# CALC3_IPGW_ICONT register map
Vendor: Texas Instruments
Peripheral module from a debugger description file (folder DRA75x_DRA74x).
Registers are 32-bit, access not given, reset 0x0 unless marked. A register's access mark holds for its fields unless they carry their own. Offsets are as the file gives them; lines under a group give offsets from that group; [hi:lo] are bit positions; {n}, {i} and the like mark numbered series; 'fields as' and 'values as' point back to an identical list; <NAME> marks a mode.

## CALC3_IPGW_ICONT
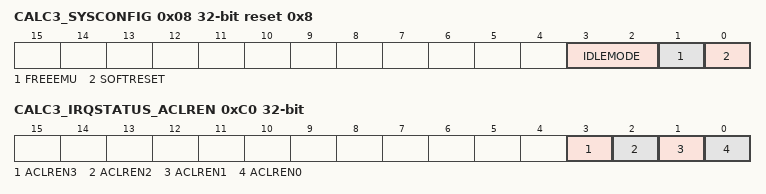
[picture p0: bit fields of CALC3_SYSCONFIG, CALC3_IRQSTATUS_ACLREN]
0x08 CALC3_SYSCONFIG access per field reset 0x8 — Clock management configuration
  [3:2] IDLEMODE rw — Configuration of the local target state management mode.By definition, target can handle read/write transaction as long as it is out of IDLE state. . Backup mode, for debug only. . Backup mode, for debug only. . IP module shall not generate (IRQ- or DMA-request-related) wakeup events. . IP module may generate (IRQ- or DMA-request-related) wakeup events when in IDLE state. .
    0=IDLE_IDLE_IP_0 (Force-idle mode: local target's IDLE state follows (acknowledges) the system's IDLE requests unconditionally; that is, regardless of the IP module's internal requirements.); 1=IDLE_1 (No-idle mode: local target never enters IDLE state.); 2=IDLE_IP_2 (Smart-idle mode: local target's IDLE state eventually follows (acknowledges) the system's idle requests, depending on the IP module's internal requirements.); 3=IDLE_IDLE_IP_3 (Smart-idle wakeup-capable mode: local target's IDLE state eventually follows (acknowledges) the system's IDLE requests, depending on the IP module's internal requirements.)
  [1] FREEEMU rw — Sensitivity to emulation (debug) suspend input signal.
    0=IP_0 (IP module is sensitive to emulation suspend); 1=IP_1 (IP module is not sensitive to emulation suspend)
  [0] SOFTRESET rw — Software reset
    0=Reset_done,_no_pending_action; 1=Reset_(software_or_other)_ongoing; 0=No_action; 1=Initiate_software_reset
0x0C CALC3_IRQ_EOI access per field — End Of Interrupt number specification
  [1:0] LINE_NUMBER rw — Software End Of Interrupt (EOI) control. Write number of interrupt output.
    0=EOI_(LSE)_0 (EOI for interrupt output int_end load (LSE)); 1=EOI_(CALC3_1 (EOI for interrupt output int_end (CALC3 Core)); 2=EOI_(LSE)_2 (EOI for interrupt output int_end store (LSE)); 3=EOI_(LSE)_3 (EOI for interrupt output int_undef (LSE)); 0=Reads_always_0_(no_EOI_memory)
0x14 CALC3_IPQSTATUS_RAW_0 — Per-event raw interrupt status vector, int_end load (LSE). Raw status is set even if event is not enabled. Write 1 to set the (raw) status, mostly for debug.
  [0] EVENT0 — Settable raw status for int_end load (LSE). Write 0: No action Read 0: No event pending Read 1: Event pending Write 1: Set event (debug) (access RW W1toSet)
0x18 CALC3_IPQSTATUS_RAW_1 — Per-event raw interrupt status vector, int_end (CALC3 core). Raw status is set even if event is not enabled. Write 1 to set the (raw) status, mostly for debug.
  [0] EVENT0 — Settable raw status for int_end (CALC3 core). Write 0: No action Read 0: No event pending Read 1: Event pending Write 1: Set event (debug) (access RW W1toSet)
0x1C CALC3_IPQSTATUS_RAW_2 — Per-event raw interrupt status vector, int_end store (LSE). Raw status is set even if event is not enabled. Write 1 to set the (raw) status, mostly for debug.
  [0] EVENT0 — Settable raw status for int_end store (LSE). Write 0: No action Read 0: No event pending Read 1: Event pending Write 1: Set event (debug) (access RW W1toSet)
0x20 CALC3_IPQSTATUS_RAW_3 — Per-event raw interrupt status vector, int_undef (LSE). Raw status is set even if event is not enabled. Write 1 to set the (raw) status, mostly for debug.
  [0] EVENT0 — Settable raw status for int_undef (LSE). Write 0: No action Read 0: No event pending Read 1: Event pending Write 1: Set event (debug) (access RW W1toSet)
0x30 CALC3_IRQSTATUS_0 — Per-event 'enabled' interrupt status vector, int_end load (LSE). Enabled status is not set unless event is enabled. Write 1 to clear the status after interrupt has been serviced (raw status gets cleared, that is, even if not enabled).
  [0] EVENT0 — Clearable, enabled status for int_end load (LSE). Write 0: No action Read 0: No (enabled) event pending Read 1: Event pending Write 1: Clear (raw) event (access RW W1toClr)
0x34 CALC3_IRQSTATUS_1 — Per-event 'enabled' interrupt status vector, int_end (CALC3 Core). Enabled status is not set unless event is enabled. Write 1 to clear the status after interrupt has been serviced (raw status gets cleared, that is, even if not enabled).
  [0] EVENT0 — Clearable, enabled status for int_end (CALC3 core). Write 0: No action Read 0: No (enabled) event pending Read 1: Event pending Write 1: Clear (raw) event (access RW W1toClr)
0x38 CALC3_IRQSTATUS_2 — Per-event 'enabled' interrupt status vector, int_end store (LSE). Enabled status is not set unless event is enabled. Write 1 to clear the status after interrupt has been serviced (raw status gets cleared, that is, even if not enabled).
  [0] EVENT0 — Clearable, enabled status for int_end store (LSE) Write 0: No action Read 0: No (enabled) event pending Read 1: Event pending Write 1: Clear (raw) event (access RW W1toClr)
0x3C CALC3_IRQSTATUS_3 — Per-event 'enabled' interrupt status vector, int_undef (LSE). Enabled status is not set unless event is enabled. Write 1 to clear the status after interrupt has been serviced (raw status gets cleared, that is, even if not enabled).
  [0] EVENT0 — Clearable, enabled status for int_undef (LSE). Write 0: No action Read 0: No (enabled) event pending Read 1: Event pending Write 1: Clear (raw) event (access RW W1toClr)
0x4C CALC3_IRQENABLE_SET_0 — Per-event interrupt enable bit vector, int_end load (LSE). Write 1 to set (enable interrupt). Readout equal to corresponding _CLR register.
  [0] ENABLE0 — Enable for int_end load (LSE) Write 0: No action Read 0: Interrupt disabled (masked) Read 1: Interrupt enabled Write 1: Enable interrupt (access RW W1toSet)
0x50 CALC3_IRQENABLE_SET_1 — Per-event interrupt enable bit vector, int_end (CALC3 core). Write 1 to set (enable interrupt). Readout equal to corresponding _CLR register.
  [0] ENABLE0 — Enable for int_end (CALC3 core) Write 0: No action Read 0: Interrupt disabled (masked) Read 1: Interrupt enabled Write 1: Enable interrupt (access RW W1toSet)
0x54 CALC3_IRQENABLE_SET_2 — Per-event interrupt enable bit vector, int_end store (LSE). Write 1 to set (enable interrupt). Readout equal to corresponding _CLR register.
  [0] ENABLE0 — Enable for int_end store (LSE) Write 0: No action Read 0: Interrupt disabled (masked) Read 1: Interrupt enabled Write 1: Enable interrupt (access RW W1toSet)
0x58 CALC3_IRQENABLE_SET_3 — Per-event interrupt enable bit vector, int_undef (LSE). Write 1 to set (enable interrupt). Readout equal to corresponding _CLR register.
  [0] ENABLE0 — Enable for int_undef (LSE) Write 0: No action Read 0: Interrupt disabled (masked) Read 1: Interrupt enabled Write 1: Enable interrupt (access RW W1toSet)
0x68 CALC3_IRQENABLE_CLR_0 — Per-event interrupt enable bit vector, int_end load (LSE). Write 1 to clear (disable interrupt). Readout equal to corresponding _SET register.
  [0] ENABLE0 — Enable for int_end load (LSE) Write 0: No action Read 0: Interrupt disabled (masked) Read 1: Interrupt enabled Write 1: Disable interrupt (access RW W1toClr)
0x6C CALC3_IRQENABLE_CLR_1 — Per-event interrupt enable bit vector, int_end (CALC3 core). Write 1 to clear (disable interrupt). Readout equal to corresponding _SET register.
  [0] ENABLE0 — Enable for int_end (CALC3 core) Write 0: No action Read 0: Interrupt disabled (masked) Read 1: Interrupt enabled Write 1: Disable interrupt (access RW W1toClr)
0x70 CALC3_IRQENABLE_CLR_2 — Per-event interrupt enable bit vector, int_end store (LSE). Write 1 to clear (disable interrupt). Readout equal to corresponding _SET register.
  [0] ENABLE0 — Enable for int_end store (LSE) Write 0: No action Read 0: Interrupt disabled (masked) Read 1: Interrupt enabled Write 1: Disable interrupt (access RW W1toClr)
0x74 CALC3_IRQENABLE_CLR_3 — Per-event interrupt enable bit vector, int_undef (LSE). Write 1 to clear (disable interrupt). Readout equal to corresponding _SET register.
  [0] ENABLE0 — Enable for int_undef (LSE) Write 0: No action Read 0: Interrupt disabled (masked) Read 1: Interrupt enabled Write 1: Disable interrupt (access RW W1toClr)
0xC0 CALC3_IRQSTATUS_ACLREN access per field — Auto Clear enable
  [3] ACLREN3 rw — For int_undef (LSE)
  [2] ACLREN2 rw — For int_end store (LSE)
  [1] ACLREN1 rw — For int_end (CALC3 core)
  [0] ACLREN0 rw — For int_end load (LSE)
